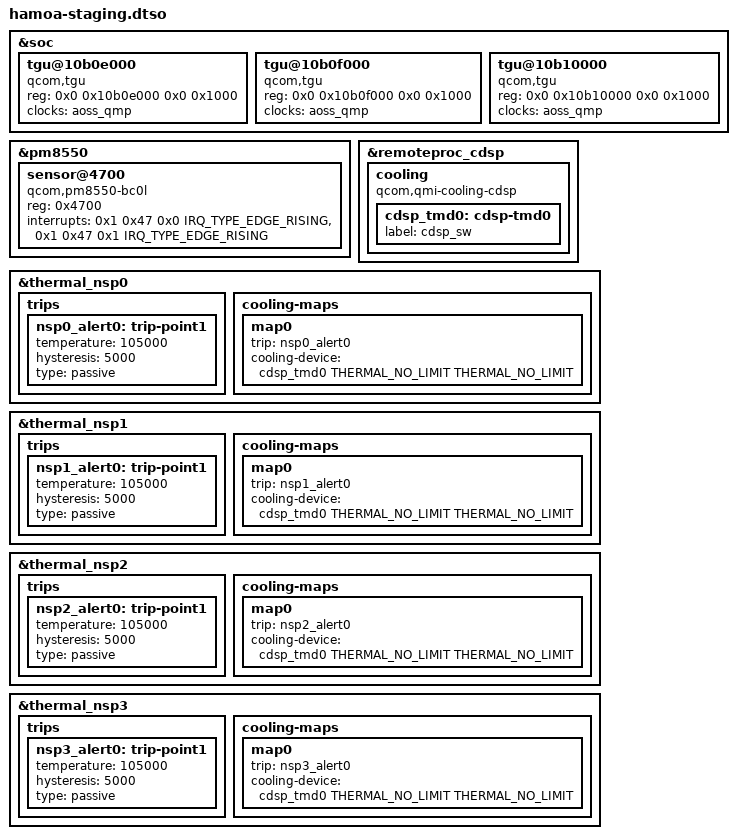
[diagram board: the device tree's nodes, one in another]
// SPDX-License-Identifier: BSD-3-Clause
/*
 * Copyright (c) Qualcomm Technologies, Inc. and/or its subsidiaries.
 *
 * Hamoa staging overlay - add staging-specific device tree modifications here.
 */

/dts-v1/;
/plugin/;

#include <dt-bindings/interrupt-controller/irq.h>
#include <dt-bindings/thermal/thermal.h>

&soc {
	tgu@10b0e000 {
		compatible = "qcom,tgu", "arm,primecell";
		reg = <0x0 0x10b0e000 0x0 0x1000>;

		clocks = <&aoss_qmp>;
		clock-names = "apb_pclk";
	};

	tgu@10b0f000 {
		compatible = "qcom,tgu", "arm,primecell";
		reg = <0x0 0x10b0f000 0x0 0x1000>;

		clocks = <&aoss_qmp>;
		clock-names = "apb_pclk";
	};

	tgu@10b10000 {
		compatible = "qcom,tgu", "arm,primecell";
		reg = <0x0 0x10b10000 0x0 0x1000>;

		clocks = <&aoss_qmp>;
		clock-names = "apb_pclk";
	};
};

&pm8550 {
	sensor@4700 {
		compatible = "qcom,pm8550-bc0l", "qcom,bcl-v3-core";
		reg = <0x4700>;
		interrupts = <0x1 0x47 0x0 IRQ_TYPE_EDGE_RISING>,
			     <0x1 0x47 0x1 IRQ_TYPE_EDGE_RISING>;
		interrupt-names = "bcl-max-min",
				  "bcl-critical";
	};
};

&remoteproc_cdsp {
	cooling {
		compatible = "qcom,qmi-cooling-cdsp";

		cdsp_tmd0: cdsp-tmd0 {
			label = "cdsp_sw";
			#cooling-cells = <2>;
		};
	};
};

&thermal_nsp0 {
	trips {
		nsp0_alert0: trip-point1 {
			temperature = <105000>;
			hysteresis = <5000>;
			type = "passive";
		};
	};

	cooling-maps {
		map0 {
			trip = <&nsp0_alert0>;
			cooling-device = <&cdsp_tmd0 THERMAL_NO_LIMIT THERMAL_NO_LIMIT>;
		};
	};
};

&thermal_nsp1 {
	trips {
		nsp1_alert0: trip-point1 {
			temperature = <105000>;
			hysteresis = <5000>;
			type = "passive";
		};
	};

	cooling-maps {
		map0 {
			trip = <&nsp1_alert0>;
			cooling-device = <&cdsp_tmd0 THERMAL_NO_LIMIT THERMAL_NO_LIMIT>;
		};
	};
};

&thermal_nsp2 {
	trips {
		nsp2_alert0: trip-point1 {
			temperature = <105000>;
			hysteresis = <5000>;
			type = "passive";
		};
	};

	cooling-maps {
		map0 {
			trip = <&nsp2_alert0>;
			cooling-device = <&cdsp_tmd0 THERMAL_NO_LIMIT THERMAL_NO_LIMIT>;
		};
	};
};

&thermal_nsp3 {
	trips {
		nsp3_alert0: trip-point1 {
			temperature = <105000>;
			hysteresis = <5000>;
			type = "passive";
		};
	};

	cooling-maps {
		map0 {
			trip = <&nsp3_alert0>;
			cooling-device = <&cdsp_tmd0 THERMAL_NO_LIMIT THERMAL_NO_LIMIT>;
		};
	};
};

